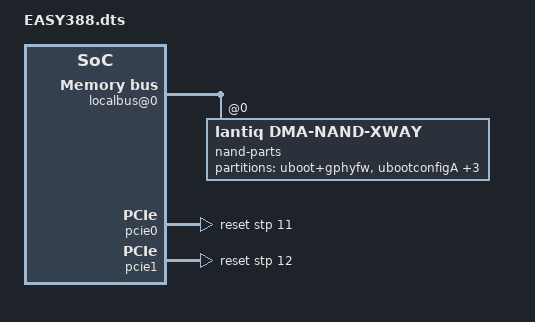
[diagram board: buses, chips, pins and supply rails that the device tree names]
/dts-v1/;


/include/ "EASY388.dtsi"

/ {
	fpi@10000000 {
		localbus@0 {
			ranges = <0 0 0x4000000 0x3ffffff>;
			nand-parts@0 {
				compatible = "lantiq,dma-nand-xway";
				lantiq,cs = <1>;
				bank-width = <2>;
				reg = <0 0x0 0x2000000>;
				#address-cells = <1>;
				#size-cells = <1>;
				lantiq,eccmode = <1>;
				lantiq,ecclocation = <0>;
				lantiq,eccstrength = <0>;

				partition@0 {
					label = "uboot+gphyfw";
					reg = <0x000000 0x200000>;
				};

				partition@200000 {
					label = "ubootconfigA";
					reg = <0x200000 0x400000>;
				};

				partition@600000 {
					label = "ubootconfigB";
					reg = <0x600000 0x400000>;
				};

				partition@a00000 {
					label = "system_sw";
					reg = <0xa00000 0x1f400000>;
				};

				partition@1fe00000 {
					label = "res";
					reg = <0x1fe00000 0x60200000>;
				};

			};
		};
	};
};

&xrx388_cpuclocks {
	status = "okay";
};
&pcie0 {
	status = "ok";
	reset-gpio = <&stp 11 0>;
	lantiq,rst-high-active = <0>; /* 0 - low activ, 1 -- high active */
	lantiq,rst-interval = <200>; /* in mili-seconds, up to 500 ms*/
	lantiq,inbound-swap = <1>; /* 0 -- no swap, 1 -- swap */
	lantiq,outbound-swap = <0>; /* 0 -- no swap, 1 -- swap */
	lantiq,phy-mode = <0>; /* 0 -36Mhz, 1 - 36MHzSSC, 2 - 25Mhz, 3 - 25MHzSSC, 4 - 100MHz */
};

&pcie1 {
	status = "ok";
	reset-gpio = <&stp 12 0>;
	lantiq,rst-high-active = <0>; /* 0 - low activ, 1 -- high active */
	lantiq,rst-interval = <200>; /* in mili-seconds, up to 500 ms*/
	lantiq,inbound-swap = <1>; /* 0 -- no swap, 1 -- swap */
	lantiq,outbound-swap = <0>; /* 0 -- no swap, 1 -- swap */
	lantiq,phy-mode = <0>; /* 0 -36Mhz, 1 - 36MHzSSC, 2 - 25Mhz, 3 - 25MHzSSC, 4 - 100MHz */
};
